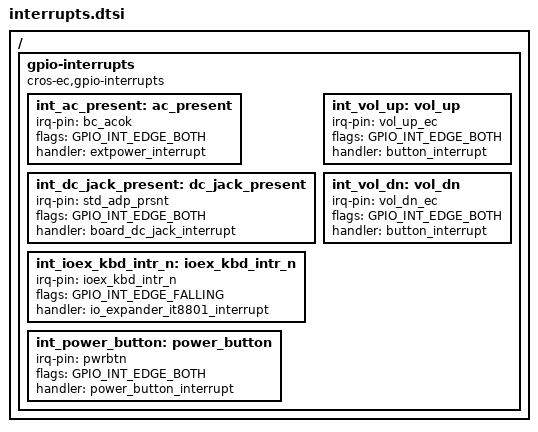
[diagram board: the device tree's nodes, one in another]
/* Copyright 2024 The ChromiumOS Authors
 * Use of this source code is governed by a BSD-style license that can be
 * found in the LICENSE file.
 */
/ {
	gpio-interrupts {
		compatible = "cros-ec,gpio-interrupts";

		int_ac_present: ac_present {
			irq-pin = <&bc_acok>;
			flags = <GPIO_INT_EDGE_BOTH>;
			handler = "extpower_interrupt";
		};
		int_dc_jack_present: dc_jack_present {
			irq-pin = <&std_adp_prsnt>;
			flags = <GPIO_INT_EDGE_BOTH>;
			handler = "board_dc_jack_interrupt";
		};
		int_ioex_kbd_intr_n: ioex_kbd_intr_n {
			irq-pin = <&ioex_kbd_intr_n>;
			flags = <GPIO_INT_EDGE_FALLING>;
			handler = "io_expander_it8801_interrupt";
		};
		int_power_button: power_button {
			irq-pin = <&pwrbtn>;
			flags = <GPIO_INT_EDGE_BOTH>;
			handler = "power_button_interrupt";
		};
		int_vol_up: vol_up {
			irq-pin = <&vol_up_ec>;
			flags = <GPIO_INT_EDGE_BOTH>;
			handler = "button_interrupt";
		};
		int_vol_dn: vol_dn {
			irq-pin = <&vol_dn_ec>;
			flags = <GPIO_INT_EDGE_BOTH>;
			handler = "button_interrupt";
		};
	};
};
